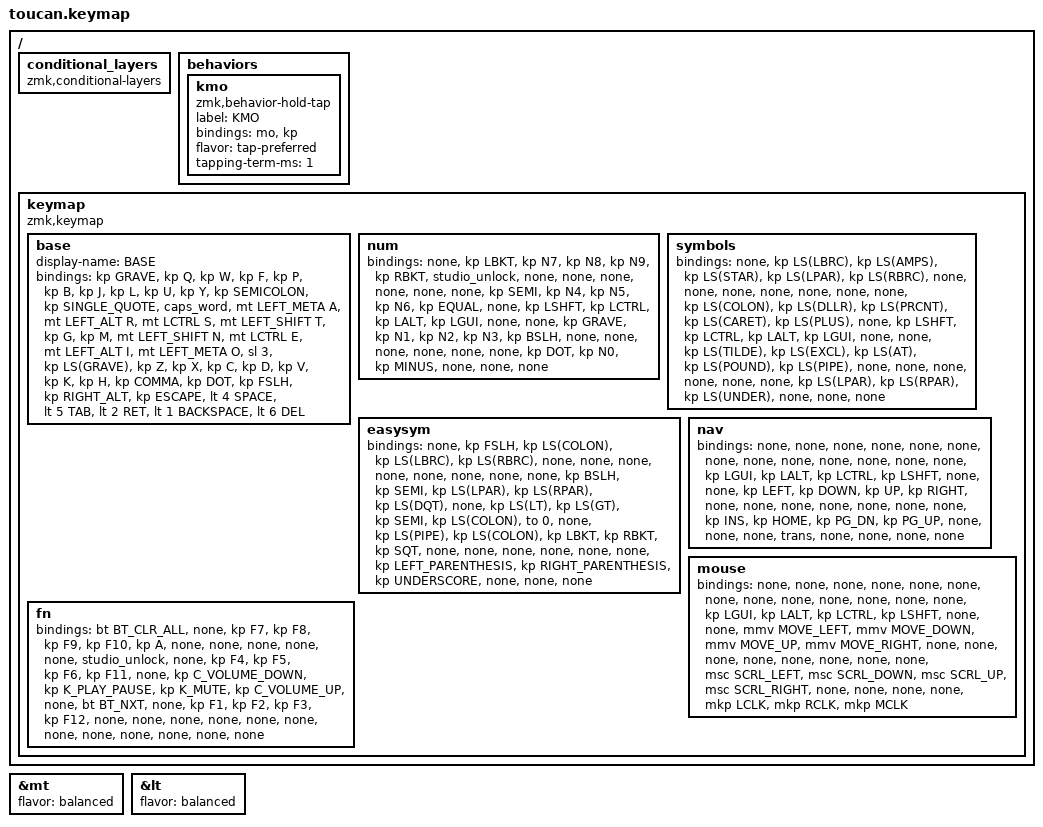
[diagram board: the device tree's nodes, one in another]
#include <behaviors.dtsi>
#include <dt-bindings/zmk/bt.h>
#include <dt-bindings/zmk/keys.h>
#include <dt-bindings/zmk/pointing.h>

#define BASE 0
#define NAV  1
#define SYM  2
#define ADJ  3

&mt { flavor = "balanced"; };

&lt { flavor = "balanced"; };

/ {
    conditional_layers { compatible = "zmk,conditional-layers"; };

    behaviors {
        kmo: kmo {
            compatible = "zmk,behavior-hold-tap";
            label = "KMO";
            bindings = <&mo>, <&kp>;

            #binding-cells = <2>;
            flavor = "tap-preferred";
            tapping-term-ms = <1>;
        };
    };

    keymap {
        compatible = "zmk,keymap";

        base {
            display-name = "BASE";
            bindings = <
&kp GRAVE  &kp Q  &kp W  &kp F  &kp P  &kp B  &kp J  &kp L  &kp U  &kp Y  &kp SEMICOLON  &kp SINGLE_QUOTE  &caps_word  &mt LEFT_META A  &mt LEFT_ALT R  &mt LCTRL S  &mt LEFT_SHIFT T  &kp G  &kp M  &mt LEFT_SHIFT N  &mt LCTRL E  &mt LEFT_ALT I  &mt LEFT_META O  &sl 3  &kp LS(GRAVE)  &kp Z  &kp X  &kp C  &kp D  &kp V  &kp K  &kp H  &kp COMMA  &kp DOT  &kp FSLH  &kp RIGHT_ALT  &kp ESCAPE  &lt 4 SPACE  &lt 5 TAB  &lt 2 RET  &lt 1 BACKSPACE  &lt 6 DEL
            >;
        };

        num {
            bindings = <
&none  &kp LBKT  &kp N7  &kp N8  &kp N9  &kp RBKT  &studio_unlock  &none  &none  &none  &none  &none  &none  &kp SEMI  &kp N4  &kp N5  &kp N6  &kp EQUAL  &none  &kp LSHFT  &kp LCTRL  &kp LALT  &kp LGUI  &none  &none  &kp GRAVE  &kp N1  &kp N2  &kp N3  &kp BSLH  &none  &none  &none  &none  &none  &none  &kp DOT  &kp N0  &kp MINUS  &none  &none  &none
            >;
        };

        symbols {
            bindings = <
&none  &kp LS(LBRC)  &kp LS(AMPS)  &kp LS(STAR)  &kp LS(LPAR)  &kp LS(RBRC)  &none  &none  &none  &none  &none  &none  &none  &kp LS(COLON)  &kp LS(DLLR)  &kp LS(PRCNT)  &kp LS(CARET)  &kp LS(PLUS)  &none  &kp LSHFT  &kp LCTRL  &kp LALT  &kp LGUI  &none  &none  &kp LS(TILDE)  &kp LS(EXCL)  &kp LS(AT)  &kp LS(POUND)  &kp LS(PIPE)  &none  &none  &none  &none  &none  &none  &kp LS(LPAR)  &kp LS(RPAR)  &kp LS(UNDER)  &none  &none  &none
            >;
        };

        easysym {
            bindings = <
&none  &kp FSLH  &kp LS(COLON)  &kp LS(LBRC)  &kp LS(RBRC)  &none  &none  &none  &none  &none  &none  &none  &none  &kp BSLH  &kp SEMI  &kp LS(LPAR)  &kp LS(RPAR)  &kp LS(DQT)  &none  &kp LS(LT)  &kp LS(GT)  &kp SEMI  &kp LS(COLON)  &to 0  &none  &kp LS(PIPE)  &kp LS(COLON)  &kp LBKT  &kp RBKT  &kp SQT  &none  &none  &none  &none  &none  &none  &kp LEFT_PARENTHESIS  &kp RIGHT_PARENTHESIS  &kp UNDERSCORE  &none  &none  &none
            >;
        };

        nav {
            bindings = <
&none  &none  &none  &none  &none  &none  &none  &none  &none  &none  &none  &none  &none  &kp LGUI  &kp LALT  &kp LCTRL  &kp LSHFT  &none  &none  &kp LEFT  &kp DOWN  &kp UP  &kp RIGHT  &none  &none  &none  &none  &none  &none  &none  &kp INS  &kp HOME  &kp PG_DN  &kp PG_UP  &none  &none  &none  &trans  &none  &none  &none  &none
            >;
        };

        mouse {
            bindings = <
&none  &none  &none  &none  &none  &none  &none  &none  &none  &none  &none  &none  &none  &kp LGUI  &kp LALT  &kp LCTRL  &kp LSHFT  &none  &none  &mmv MOVE_LEFT  &mmv MOVE_DOWN  &mmv MOVE_UP  &mmv MOVE_RIGHT  &none  &none  &none  &none  &none  &none  &none  &none  &msc SCRL_LEFT  &msc SCRL_DOWN  &msc SCRL_UP  &msc SCRL_RIGHT  &none  &none  &none  &none  &mkp LCLK  &mkp RCLK  &mkp MCLK
            >;
        };

        fn {
            bindings = <
&bt BT_CLR_ALL  &none  &kp F7  &kp F8  &kp F9  &kp F10  &kp A  &none  &none  &none  &none  &none  &studio_unlock  &none  &kp F4  &kp F5  &kp F6  &kp F11  &none  &kp C_VOLUME_DOWN  &kp K_PLAY_PAUSE  &kp K_MUTE  &kp C_VOLUME_UP  &none  &bt BT_NXT  &none  &kp F1  &kp F2  &kp F3  &kp F12  &none  &none  &none  &none  &none  &none  &none  &none  &none  &none  &none  &none
            >;
        };
    };
};
